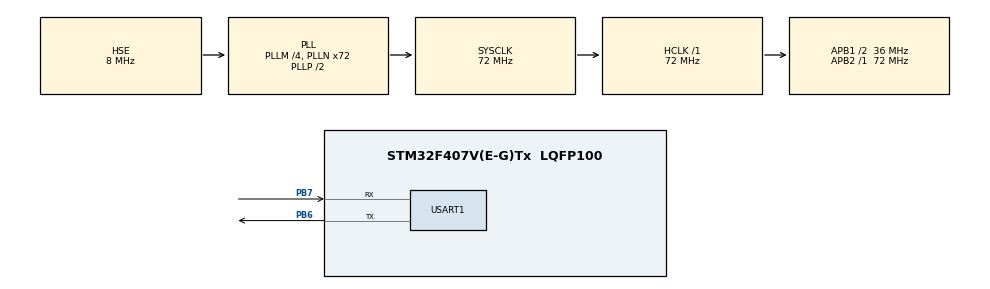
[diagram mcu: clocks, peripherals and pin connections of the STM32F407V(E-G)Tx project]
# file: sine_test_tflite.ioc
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Mcu.Family=STM32F4
Mcu.Name=STM32F407V(E-G)Tx
Mcu.Package=LQFP100
NVIC.PriorityGroup=NVIC_PRIORITYGROUP_4
NVIC.USART1_IRQn=true\:0\:0\:false\:false\:true\:true\:true\:true
PB6.Mode=Asynchronous
PB6.Signal=USART1_TX
PB7.Mode=Asynchronous
PB7.Signal=USART1_RX
PH0-OSC_IN.Mode=HSE-External-Oscillator
PH0-OSC_IN.Signal=RCC_OSC_IN
PH1-OSC_OUT.Mode=HSE-External-Oscillator
PH1-OSC_OUT.Signal=RCC_OSC_OUT
ProjectManager.HeapSize=0x800
ProjectManager.StackSize=0x800
ProjectManager.TargetToolchain=STM32CubeIDE
RCC.48MHZClocksFreq_Value=36000000
RCC.AHBFreq_Value=72000000
RCC.APB1CLKDivider=RCC_HCLK_DIV2
RCC.APB1Freq_Value=36000000
RCC.APB1TimFreq_Value=72000000
RCC.APB2Freq_Value=72000000
RCC.APB2TimFreq_Value=72000000
RCC.CortexFreq_Value=72000000
RCC.HCLKFreq_Value=72000000
RCC.HSE_VALUE=8000000
RCC.HSI_VALUE=16000000
RCC.LSE_VALUE=32768
RCC.PLLM=4
RCC.PLLN=72
RCC.PLLSourceVirtual=RCC_PLLSOURCE_HSE
RCC.SYSCLKFreq_VALUE=72000000
RCC.SYSCLKSource=RCC_SYSCLKSOURCE_PLLCLK
RCC.VCOOutputFreq_Value=144000000
STMicroelectronics.X-CUBE-AI.5.2.0.ActivationBufferSizeList=136
STMicroelectronics.X-CUBE-AI.5.2.0.HeapSize=0x800
STMicroelectronics.X-CUBE-AI.5.2.0.InternalRamActivationBufferMaxSize=AI_SINE_APPROX_DATA_ACTIVATIONS_SIZE
STMicroelectronics.X-CUBE-AI.5.2.0.LatestDirectoryUsed-19dee2b300dac31c79e0e28ca1c847129e5e920f2f98e422ef95e2adb721cc00=C\:\\Users\\Ivan\\Desktop\\tf-lite-stm32
STMicroelectronics.X-CUBE-AI.5.2.0.MaximumNumberOfInputLayer=1
STMicroelectronics.X-CUBE-AI.5.2.0.MaximumNumberOfOutputLayer=1
STMicroelectronics.X-CUBE-AI.5.2.0.MaximumSizeOfInputLayer=AI_SINE_APPROX_IN_1_SIZE_BYTES
STMicroelectronics.X-CUBE-AI.5.2.0.MaximumSizeOfOutputLayer=AI_SINE_APPROX_OUT_1_SIZE_BYTES
STMicroelectronics.X-CUBE-AI.5.2.0.ModelActualCompression-19dee2b300dac31c79e0e28ca1c847129e5e920f2f98e422ef95e2adb721cc00=0.0
STMicroelectronics.X-CUBE-AI.5.2.0.ModelCompression-19dee2b300dac31c79e0e28ca1c847129e5e920f2f98e422ef95e2adb721cc00=1
STMicroelectronics.X-CUBE-AI.5.2.0.ModelFlashOccupation-19dee2b300dac31c79e0e28ca1c847129e5e920f2f98e422ef95e2adb721cc00=1284
STMicroelectronics.X-CUBE-AI.5.2.0.ModelHashList=19dee2b300dac31c79e0e28ca1c847129e5e920f2f98e422ef95e2adb721cc00
STMicroelectronics.X-CUBE-AI.5.2.0.ModelKind-19dee2b300dac31c79e0e28ca1c847129e5e920f2f98e422ef95e2adb721cc00=TFLITE
STMicroelectronics.X-CUBE-AI.5.2.0.ModelMacc-19dee2b300dac31c79e0e28ca1c847129e5e920f2f98e422ef95e2adb721cc00=320
STMicroelectronics.X-CUBE-AI.5.2.0.ModelName-19dee2b300dac31c79e0e28ca1c847129e5e920f2f98e422ef95e2adb721cc00=sine_approx
STMicroelectronics.X-CUBE-AI.5.2.0.ModelNameList=sine_approx
STMicroelectronics.X-CUBE-AI.5.2.0.ModelRamOccupation-19dee2b300dac31c79e0e28ca1c847129e5e920f2f98e422ef95e2adb721cc00=136
STMicroelectronics.X-CUBE-AI.5.2.0.ModelStructureFile-19dee2b300dac31c79e0e28ca1c847129e5e920f2f98e422ef95e2adb721cc00=C\:\\Users\\Ivan\\Desktop\\tf-lite-stm32\\sine_model.tflite
STMicroelectronics.X-CUBE-AI.5.2.0.ModelType-19dee2b300dac31c79e0e28ca1c847129e5e920f2f98e422ef95e2adb721cc00=Saved model
STMicroelectronics.X-CUBE-AI.5.2.0.StackSize=0x800
STMicroelectronics.X-CUBE-AI.5.2.0.WorkingBufferStartAddrList=0xFFFFFFFF
STMicroelectronics.X-CUBE-AI.5.2.0.XAaCUBEAaAICcArtificialOoIntelligenceJjCore=true
USART1.VirtualMode=VM_ASYNC
VP_CRC_VS_CRC.Mode=CRC_Activate
VP_STMicroelectronics.X-CUBE-AI_VS_ArtificialOoIntelligenceJjXAaCUBEAaAI_5.2.0.Mode=ArtificialOoIntelligenceJjXAaCUBEAaAI
board=custom

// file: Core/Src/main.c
/* USER CODE BEGIN Header */
/**
  ******************************************************************************
  * @file           : main.c
  * @brief          : Main program body
  ******************************************************************************
  * @attention
  *
  * Copyright (c) 2023 STMicroelectronics.
  * All rights reserved.
  *
  * This software is licensed under terms that can be found in the LICENSE file
  * in the root directory of this software component.
  * If no LICENSE file comes with this software, it is provided AS-IS.
  *
  ******************************************************************************
  */
/* USER CODE END Header */
#include "main.h"
#include "crc.h"
#include "usart.h"
#include "gpio.h"

/* USER CODE BEGIN Includes */
#include <stdio.h>

#include "ai_datatypes_defines.h"
#include "ai_platform.h"
#include "sine_approx.h"
#include "sine_approx_data.h"
/* USER CODE END Includes */

/* USER CODE BEGIN PV */
char RX_BUFF[BUFF_SIZE];
char TX_BUFF[MSG_BUFF];
int RX_BUFF_HEAD, RX_BUFF_TAIL;
uint8_t rx_data;
/* USER CODE END PV */

void SystemClock_Config(void);

int main(void)
{
  /* USER CODE BEGIN 1 */
	char buff[BUFF_SIZE];
	int buf_len = 0;
	ai_error ai_err;
	ai_i32 nbatch;
	uint32_t timestamp;
	float y_val;

	uint8_t *tmp = 1;

	AI_ALIGNED(4) ai_u8 activations[AI_SINE_APPROX_DATA_ACTIVATIONS_SIZE];

	AI_ALIGNED(4) ai_i8 in_data[AI_SINE_APPROX_IN_1_SIZE_BYTES];
	AI_ALIGNED(4) ai_i8 out_data[AI_SINE_APPROX_OUT_1_SIZE_BYTES];

	ai_handle sine_model = AI_HANDLE_NULL;

	ai_buffer ai_input[AI_SINE_APPROX_IN_NUM] = AI_SINE_APPROX_IN;
	ai_buffer ai_output[AI_SINE_APPROX_OUT_NUM] = AI_SINE_APPROX_OUT;

	ai_network_params ai_params = {
			AI_SINE_APPROX_DATA_WEIGHTS(ai_sine_approx_data_weights_get()),
			AI_SINE_APPROX_DATA_ACTIVATIONS(activations)
	};

	ai_input[0].n_batches = 1;
	ai_input[0].data = AI_HANDLE_PTR(in_data);
	ai_output[0].n_batches = 1;
	ai_output[0].data = AI_HANDLE_PTR(out_data);
  /* USER CODE END 1 */

  /* MCU Configuration--------------------------------------------------------*/

  /* Reset of all peripherals, Initializes the Flash interface and the Systick. */
  HAL_Init();

  /* Configure the system clock */
  SystemClock_Config();

  /* Initialize all configured peripherals */
  MX_GPIO_Init();
  MX_CRC_Init();
  MX_USART1_UART_Init();
  /* USER CODE BEGIN 2 */

  buf_len = sprintf(buff, "\r\n\r\nSTM32 X-CUBE-AI Test\r\n");

  HAL_UART_Transmit_IT(&huart1, (uint8_t *)buff, buf_len);

  ai_err = ai_sine_approx_create(&sine_model, AI_SINE_APPROX_DATA_CONFIG);
  if (ai_err.type != AI_ERROR_NONE)
  {
	  buf_len = sprintf(buff, "Error: could not create NN instance\r\n");
	  HAL_UART_Transmit(&huart1, (uint8_t *)buff, buf_len, 100);
	  while(1);
  }

  if (!ai_sine_approx_init(sine_model, &ai_params))
  {
    buf_len = sprintf(buff, "Error: could not initialize NN\r\n");
    HAL_UART_Transmit(&huart1, (uint8_t *)buff, buf_len, 100);
    while(1);
  }

  /* USER CODE END 2 */

  /* Infinite loop */
  /* USER CODE BEGIN WHILE */
  while (1)
  {
	for (uint32_t i = 0; i < AI_SINE_APPROX_IN_1_SIZE; i++)
	{
	  ((ai_float *)in_data)[i] = (ai_float)2.0f;
	}

	// Perform inference
	nbatch = ai_sine_approx_run(sine_model, &ai_input[0], &ai_output[0]);
	if (nbatch != 1) {
	  buf_len = sprintf(buff, "Error: could not run inference\r\n");
	  HAL_UART_Transmit_IT(&huart1, (uint8_t *)buff, buf_len);
	}

	// Read output (predicted y) of neural network
	y_val = ((float *)out_data)[0];

	// Print output of neural network along with inference time (microseconds)
	buf_len = sprintf(buff,"Output: %f \r\n",y_val);
	HAL_UART_Transmit_IT(&huart1, (uint8_t *)buff, buf_len);

	// Wait before doing it again
	HAL_Delay(1000);
    /* USER CODE END WHILE */

  }
}

void SystemClock_Config(void)
{
  RCC_OscInitTypeDef RCC_OscInitStruct = {0};
  RCC_ClkInitTypeDef RCC_ClkInitStruct = {0};

  /** Configure the main internal regulator output voltage
  */
  __HAL_RCC_PWR_CLK_ENABLE();
  __HAL_PWR_VOLTAGESCALING_CONFIG(PWR_REGULATOR_VOLTAGE_SCALE1);

  /** Initializes the RCC Oscillators according to the specified parameters
  * in the RCC_OscInitTypeDef structure.
  */
  RCC_OscInitStruct.OscillatorType = RCC_OSCILLATORTYPE_HSE;
  RCC_OscInitStruct.HSEState = RCC_HSE_ON;
  RCC_OscInitStruct.PLL.PLLState = RCC_PLL_ON;
  RCC_OscInitStruct.PLL.PLLSource = RCC_PLLSOURCE_HSE;
  RCC_OscInitStruct.PLL.PLLM = 4;
  RCC_OscInitStruct.PLL.PLLN = 72;
  RCC_OscInitStruct.PLL.PLLP = RCC_PLLP_DIV2;
  RCC_OscInitStruct.PLL.PLLQ = 4;
  if (HAL_RCC_OscConfig(&RCC_OscInitStruct) != HAL_OK)
  {
    Error_Handler();
  }

  /** Initializes the CPU, AHB and APB buses clocks
  */
  RCC_ClkInitStruct.ClockType = RCC_CLOCKTYPE_HCLK|RCC_CLOCKTYPE_SYSCLK
                              |RCC_CLOCKTYPE_PCLK1|RCC_CLOCKTYPE_PCLK2;
  RCC_ClkInitStruct.SYSCLKSource = RCC_SYSCLKSOURCE_PLLCLK;
  RCC_ClkInitStruct.AHBCLKDivider = RCC_SYSCLK_DIV1;
  RCC_ClkInitStruct.APB1CLKDivider = RCC_HCLK_DIV2;
  RCC_ClkInitStruct.APB2CLKDivider = RCC_HCLK_DIV1;

  if (HAL_RCC_ClockConfig(&RCC_ClkInitStruct, FLASH_LATENCY_2) != HAL_OK)
  {
    Error_Handler();
  }
}

void Error_Handler(void)
{
  __disable_irq();
  while (1)
  {
  }
}
